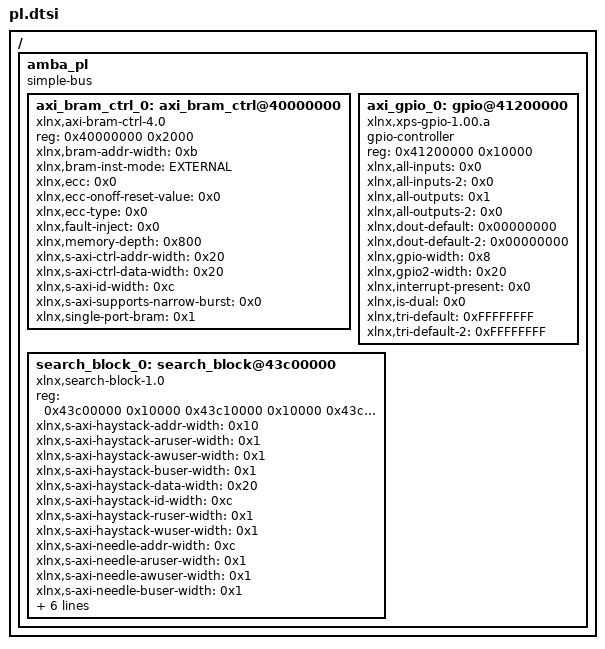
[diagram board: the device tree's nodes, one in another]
/*
 * CAUTION: This file is automatically generated by Xilinx.
 * Version:  
 * Today is: Sun May 24 12:50:19 2015
*/


/ {
	amba_pl: amba_pl {
		#address-cells = <1>;
		#size-cells = <1>;
		compatible = "simple-bus";
		ranges ;
		axi_bram_ctrl_0: axi_bram_ctrl@40000000 {
			compatible = "xlnx,axi-bram-ctrl-4.0";
			reg = <0x40000000 0x2000>;
			xlnx,bram-addr-width = <0xb>;
			xlnx,bram-inst-mode = "EXTERNAL";
			xlnx,ecc = <0x0>;
			xlnx,ecc-onoff-reset-value = <0x0>;
			xlnx,ecc-type = <0x0>;
			xlnx,fault-inject = <0x0>;
			xlnx,memory-depth = <0x800>;
			xlnx,s-axi-ctrl-addr-width = <0x20>;
			xlnx,s-axi-ctrl-data-width = <0x20>;
			xlnx,s-axi-id-width = <0xc>;
			xlnx,s-axi-supports-narrow-burst = <0x0>;
			xlnx,single-port-bram = <0x1>;
		};
		axi_gpio_0: gpio@41200000 {
			#gpio-cells = <2>;
			compatible = "xlnx,xps-gpio-1.00.a";
			gpio-controller ;
			reg = <0x41200000 0x10000>;
			xlnx,all-inputs = <0x0>;
			xlnx,all-inputs-2 = <0x0>;
			xlnx,all-outputs = <0x1>;
			xlnx,all-outputs-2 = <0x0>;
			xlnx,dout-default = <0x00000000>;
			xlnx,dout-default-2 = <0x00000000>;
			xlnx,gpio-width = <0x8>;
			xlnx,gpio2-width = <0x20>;
			xlnx,interrupt-present = <0x0>;
			xlnx,is-dual = <0x0>;
			xlnx,tri-default = <0xFFFFFFFF>;
			xlnx,tri-default-2 = <0xFFFFFFFF>;
		};
		search_block_0: search_block@43c00000 {
			compatible = "xlnx,search-block-1.0";
			reg = <0x43c00000 0x10000 0x43c10000 0x10000 0x43c20000 0x10000>;
			xlnx,s-axi-haystack-addr-width = <0x10>;
			xlnx,s-axi-haystack-aruser-width = <0x1>;
			xlnx,s-axi-haystack-awuser-width = <0x1>;
			xlnx,s-axi-haystack-buser-width = <0x1>;
			xlnx,s-axi-haystack-data-width = <0x20>;
			xlnx,s-axi-haystack-id-width = <0xc>;
			xlnx,s-axi-haystack-ruser-width = <0x1>;
			xlnx,s-axi-haystack-wuser-width = <0x1>;
			xlnx,s-axi-needle-addr-width = <0xc>;
			xlnx,s-axi-needle-aruser-width = <0x1>;
			xlnx,s-axi-needle-awuser-width = <0x1>;
			xlnx,s-axi-needle-buser-width = <0x1>;
			xlnx,s-axi-needle-data-width = <0x20>;
			xlnx,s-axi-needle-id-width = <0xc>;
			xlnx,s-axi-needle-ruser-width = <0x1>;
			xlnx,s-axi-needle-wuser-width = <0x1>;
			xlnx,s-axi-registers-addr-width = <0x4>;
			xlnx,s-axi-registers-data-width = <0x20>;
		};
	};
};
